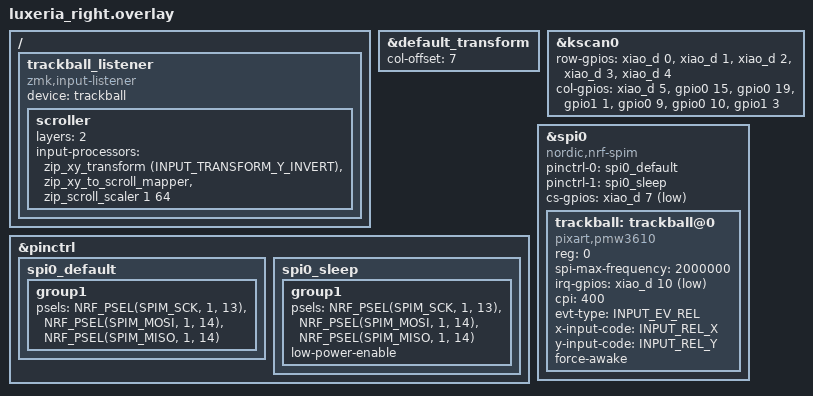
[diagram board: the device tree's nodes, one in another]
/*
 * Copyright (c) 2024 The ZMK Contributors
 * SPDX-License-Identifier: MIT
 */

#include "luxeria.dtsi"
#include <zephyr/dt-bindings/input/input-event-codes.h>
#include <dt-bindings/zmk/input_transform.h>
#include <input/processors.dtsi>

// Seeeduino XIAO BLE Plus pinout:
// D0  = &xiao_d 0  (P0.02)
// D1  = &xiao_d 1  (P0.03)
// D2  = &xiao_d 2  (P0.28)
// D3  = &xiao_d 3  (P0.29)
// D4  = &xiao_d 4  (P0.04)
// D5  = &xiao_d 5  (P0.05)
// D6  = &xiao_d 6  (P1.11) - Trackball MISO
// D7  = &xiao_d 7  (P1.12) - Trackball NCS
// D8  = &xiao_d 8  (P1.13) - Trackball SCLK
// D9  = &xiao_d 9  (P1.14) - Trackball MOSI
// D10 = &xiao_d 10 (P1.15) - Trackball MOT
// D11 = &gpio0 15  (P0.15)
// D12 = &gpio0 19  (P0.19)
// D13 = &gpio1 1   (P1.01)
// D14 = &gpio0 9   (P0.09)
// D15 = &gpio0 10  (P0.10)
// D16 = &gpio1 3   (P1.03)

&default_transform {
    col-offset = <7>;
};

&kscan0 {
    row-gpios
        = <&xiao_d 0 (GPIO_ACTIVE_HIGH | GPIO_PULL_DOWN)>
        , <&xiao_d 1 (GPIO_ACTIVE_HIGH | GPIO_PULL_DOWN)>
        , <&xiao_d 2 (GPIO_ACTIVE_HIGH | GPIO_PULL_DOWN)>
        , <&xiao_d 3 (GPIO_ACTIVE_HIGH | GPIO_PULL_DOWN)>
        , <&xiao_d 4 (GPIO_ACTIVE_HIGH | GPIO_PULL_DOWN)>
        ;
    col-gpios
        = <&xiao_d 5 GPIO_ACTIVE_HIGH>
        , <&gpio0 15 GPIO_ACTIVE_HIGH>
        , <&gpio0 19 GPIO_ACTIVE_HIGH>
        , <&gpio1 1 GPIO_ACTIVE_HIGH>
        , <&gpio0 9 GPIO_ACTIVE_HIGH>
        , <&gpio0 10 GPIO_ACTIVE_HIGH>
        , <&gpio1 3 GPIO_ACTIVE_HIGH>
        ;
};

&pinctrl {
    spi0_default: spi0_default {
        group1 {
            psels = <NRF_PSEL(SPIM_SCK, 1, 13)>,
                    <NRF_PSEL(SPIM_MOSI, 1, 14)>,
                    <NRF_PSEL(SPIM_MISO, 1, 14)>;
        };
    };

    spi0_sleep: spi0_sleep {
        group1 {
            psels = <NRF_PSEL(SPIM_SCK, 1, 13)>,
                    <NRF_PSEL(SPIM_MOSI, 1, 14)>,
                    <NRF_PSEL(SPIM_MISO, 1, 14)>;
            low-power-enable;
        };
    };
};

&spi0 {
    status = "okay";
    compatible = "nordic,nrf-spim";
    pinctrl-0 = <&spi0_default>;
    pinctrl-1 = <&spi0_sleep>;
    pinctrl-names = "default", "sleep";
    cs-gpios = <&xiao_d 7 GPIO_ACTIVE_LOW>;

    trackball: trackball@0 {
        status = "okay";
        compatible = "pixart,pmw3610";
        reg = <0>;
        spi-max-frequency = <2000000>;
        irq-gpios = <&xiao_d 10 (GPIO_ACTIVE_LOW | GPIO_PULL_UP)>;
        cpi = <400>;
        evt-type = <INPUT_EV_REL>;
        x-input-code = <INPUT_REL_X>;
        y-input-code = <INPUT_REL_Y>;
        force-awake;
    };
};

/ {
    trackball_listener {
        compatible = "zmk,input-listener";
        device = <&trackball>;

        scroller {
            layers = <2>;
            input-processors = <&zip_xy_transform (INPUT_TRANSFORM_Y_INVERT)>, <&zip_xy_to_scroll_mapper>, <&zip_scroll_scaler 1 64>;
        };
    };
};
